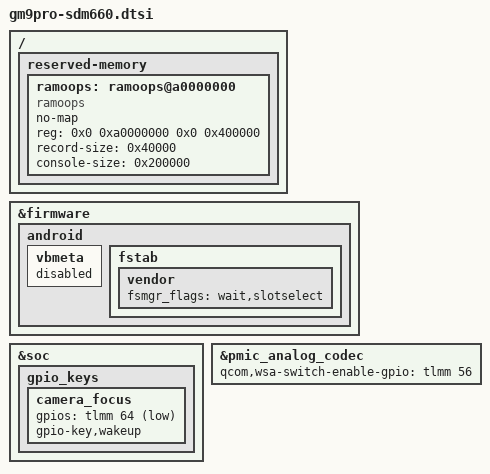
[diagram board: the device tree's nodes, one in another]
#include "gm9pro-pm660.dtsi"
#include "gm9pro-sdm660-audio.dtsi"
#include "gm9pro-sdm660-mdss.dtsi"
#include "gm9pro-sdm660-regulator.dtsi"
#include "gm9pro-sdm660-pinctrl.dtsi"

&firmware {
	android {
		vbmeta {
			status = "disabled";
		};

		fstab {
			vendor {
				fsmgr_flags = "wait,slotselect";
			};
		};
        };
};

&soc {
	gpio_keys {
		camera_focus {
			gpios = <&tlmm 64 1>;
			gpio-key,wakeup;
		};

		/delete-node/ camera_snapshot;
	};
};

/ {
    reserved-memory {
        ramoops: ramoops@a0000000 {
            compatible = "ramoops";
            no-map;
            reg = <0x0 0xa0000000 0x0 0x400000>;
            record-size = <0x40000>;
            console-size = <0x200000>;
        };
    };
};

&pmic_analog_codec {
	qcom,wsa-switch-enable-gpio = <&tlmm 56 0>;
};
